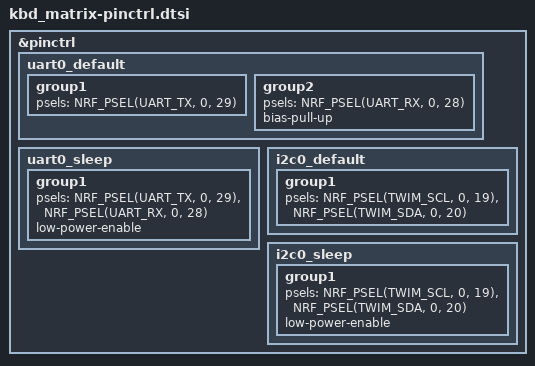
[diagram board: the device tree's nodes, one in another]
&pinctrl {
	uart0_default: uart0_default {
		group1 {
			psels = <NRF_PSEL(UART_TX, 0, 29)>;
		};
		group2 {
			psels = <NRF_PSEL(UART_RX, 0, 28)>;
			bias-pull-up;
		};
	};

	uart0_sleep: uart0_sleep {
		group1 {
			psels = <NRF_PSEL(UART_TX, 0, 29)>,
				<NRF_PSEL(UART_RX, 0, 28)>;
			low-power-enable;
		};
	};

	i2c0_default: i2c0_default {
		group1 {
			psels = <NRF_PSEL(TWIM_SCL, 0, 19)>,
				<NRF_PSEL(TWIM_SDA, 0, 20)>;
		};
	};

	i2c0_sleep: i2c0_sleep {
		group1 {
			psels = <NRF_PSEL(TWIM_SCL, 0, 19)>,
				<NRF_PSEL(TWIM_SDA, 0, 20)>;
			low-power-enable;
		};
	};
};
